# STM32H7B3ZIT6Q register map
File version: 1.0
Registers are 32-bit, access not given, reset 0x0 unless marked. A register's access mark holds for its fields unless they carry their own. Offsets are from the block's base; [hi:lo] are bit positions; {n}, {i} and the like mark numbered series; 'fields as' and 'values as' point back to an identical list.

## FMC_Bank3_R
Base 0x52004080
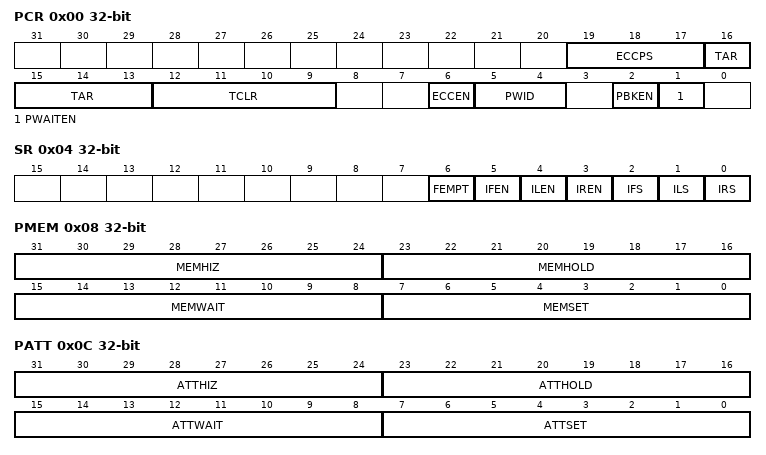
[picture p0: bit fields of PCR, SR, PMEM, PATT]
0x00 PCR
  [19:17] ECCPS, [16:13] TAR, [12:9] TCLR, [6] ECCEN, [5:4] PWID, [2] PBKEN, [1] PWAITEN
0x04 SR
  [6] FEMPT, [5] IFEN, [4] ILEN, [3] IREN, [2] IFS, [1] ILS, [0] IRS
0x08 PMEM
  [31:24] MEMHIZ, [23:16] MEMHOLD, [15:8] MEMWAIT, [7:0] MEMSET
0x0C PATT
  [31:24] ATTHIZ, [23:16] ATTHOLD, [15:8] ATTWAIT, [7:0] ATTSET
0x14 ECCR

## FMC_Bank1E_R
Base 0x52004104
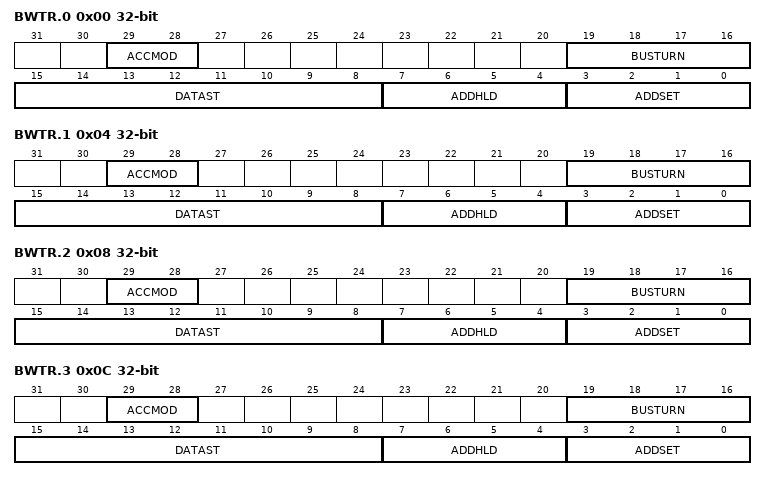
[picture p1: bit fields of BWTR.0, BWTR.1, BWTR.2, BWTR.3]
0x00 BWTR.0
  [29:28] ACCMOD, [19:16] BUSTURN, [15:8] DATAST, [7:4] ADDHLD, [3:0] ADDSET
0x04 BWTR.1
  fields as BWTR.0
0x08 BWTR.2
  fields as BWTR.0
0x0C BWTR.3
  fields as BWTR.0
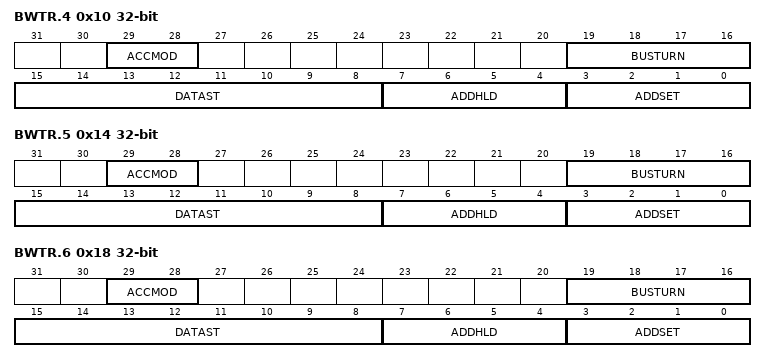
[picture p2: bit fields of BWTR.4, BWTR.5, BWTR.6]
0x10 BWTR.4
  fields as BWTR.0
0x14 BWTR.5
  fields as BWTR.0
0x18 BWTR.6
  fields as BWTR.0

## FMC_Bank5_6_R
Base 0x52004140
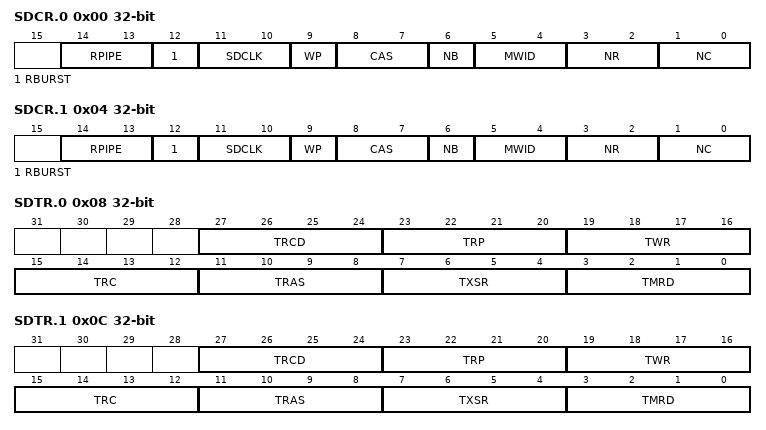
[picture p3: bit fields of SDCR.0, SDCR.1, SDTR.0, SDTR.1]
0x00 SDCR.0
  [14:13] RPIPE, [12] RBURST, [11:10] SDCLK, [9] WP, [8:7] CAS, [6] NB, [5:4] MWID, [3:2] NR, [1:0] NC
0x04 SDCR.1
  fields as SDCR.0
0x08 SDTR.0
  [27:24] TRCD, [23:20] TRP, [19:16] TWR, [15:12] TRC, [11:8] TRAS, [7:4] TXSR, [3:0] TMRD
0x0C SDTR.1
  fields as SDTR.0
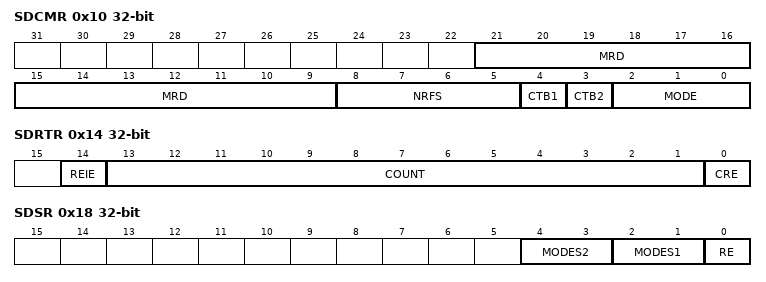
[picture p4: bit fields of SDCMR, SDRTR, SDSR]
0x10 SDCMR
  [21:9] MRD, [8:5] NRFS, [4] CTB1, [3] CTB2, [2:0] MODE
0x14 SDRTR
  [14] REIE, [13:1] COUNT, [0] CRE
0x18 SDSR
  [4:3] MODES2, [2:1] MODES1, [0] RE

## OCTOSPI1
Base 0x52005000
Same registers: OCTOSPI2 0x5200A000
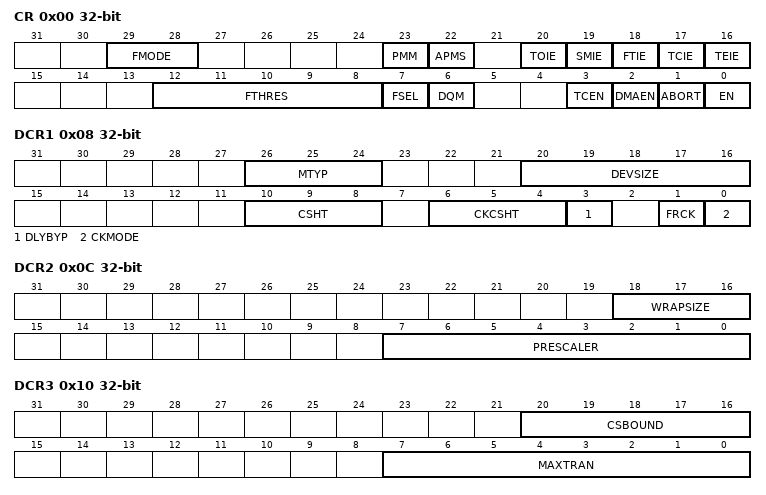
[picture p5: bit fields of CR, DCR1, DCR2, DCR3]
0x00 CR
  [29:28] FMODE, [23] PMM, [22] APMS, [20] TOIE, [19] SMIE, [18] FTIE, [17] TCIE, [16] TEIE, [12:8] FTHRES, [7] FSEL, [6] DQM, [3] TCEN, [2] DMAEN, [1] ABORT, [0] EN
0x08 DCR1
  [26:24] MTYP, [20:16] DEVSIZE, [10:8] CSHT, [6:4] CKCSHT, [3] DLYBYP, [1] FRCK, [0] CKMODE
0x0C DCR2
  [18:16] WRAPSIZE, [7:0] PRESCALER
0x10 DCR3
  [20:16] CSBOUND, [7:0] MAXTRAN
0x14 DCR4
  [31:0] REFRESH
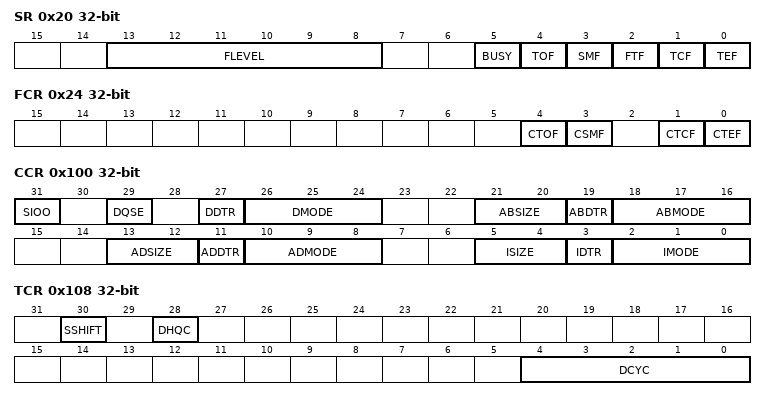
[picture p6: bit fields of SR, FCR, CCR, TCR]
0x20 SR
  [13:8] FLEVEL, [5] BUSY, [4] TOF, [3] SMF, [2] FTF, [1] TCF, [0] TEF
0x24 FCR
  [4] CTOF, [3] CSMF, [1] CTCF, [0] CTEF
0x40 DLR
  [31:0] DL
0x48 AR
  [31:0] ADDRESS
0x50 DR
  [31:0] DATA
0x80 PSMKR
  [31:0] MASK
0x88 PSMAR
  [31:0] MATCH
0x90 PIR
  [15:0] INTERVAL
0x100 CCR
  [31] SIOO, [29] DQSE, [27] DDTR, [26:24] DMODE, [21:20] ABSIZE, [19] ABDTR, [18:16] ABMODE, [13:12] ADSIZE, [11] ADDTR, [10:8] ADMODE, [5:4] ISIZE, [3] IDTR, [2:0] IMODE
0x108 TCR
  [30] SSHIFT, [28] DHQC, [4:0] DCYC
0x110 IR
  [31:0] INSTRUCTION
0x120 ABR
  [31:0] ALTERNATE
0x130 LPTR
  [15:0] TIMEOUT
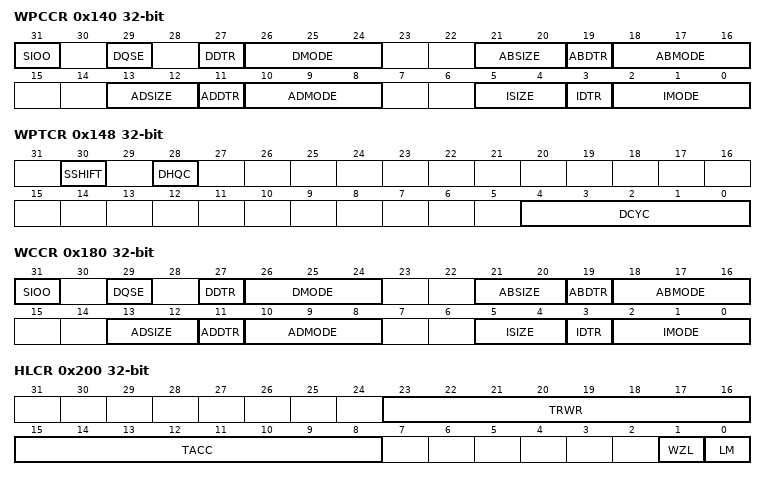
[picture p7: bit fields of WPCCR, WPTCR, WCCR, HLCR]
0x140 WPCCR
  fields as CCR
0x148 WPTCR
  [30] SSHIFT, [28] DHQC, [4:0] DCYC
0x150 WPIR
  [31:0] INSTRUCTION
0x160 WPABR
  [31:0] ALTERNATE
0x180 WCCR
  fields as CCR
0x188 WTCR
  [4:0] DCYC
0x190 WIR
  [31:0] INSTRUCTION
0x1A0 WABR
  [31:0] ALTERNATE
0x200 HLCR
  [23:16] TRWR, [15:8] TACC, [1] WZL, [0] LM
0x3EC HWCFGR
0x3F0 VER
  [7:0] VER
0x3F4 ID
0x3F8 MID

## RAMECC
Base 0x52009000
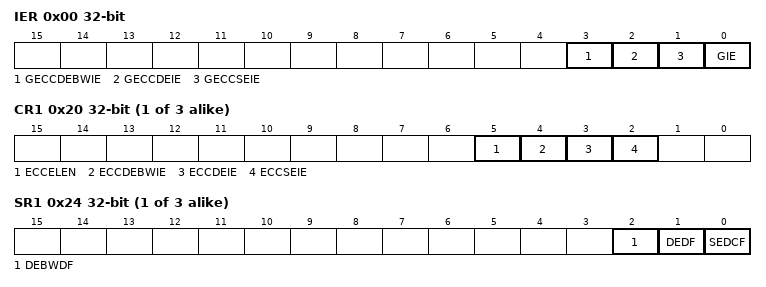
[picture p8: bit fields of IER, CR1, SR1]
0x00 IER
  [3] GECCDEBWIE, [2] GECCDEIE, [1] GECCSEIE, [0] GIE
{0x0+0x20*i} CR{i} (i=1..3)
  [5] ECCELEN, [4] ECCDEBWIE, [3] ECCDEIE, [2] ECCSEIE
{0x4+0x20*i} SR{i} (i=1..3)
  [2] DEBWDF, [1] DEDF, [0] SEDCF
{0x8+0x20*i} FAR{i} (i=1..3)
  [31:0] FDATAL
{0xC+0x20*i} FDRL{i} (i=1..3)
{0x10+0x20*i} FDRH{i} (i=1..3)
{0x14+0x20*i} FECR{i} (i=1..3)
  [31:0] FEC

## OCTOSPIM
Base 0x5200B400
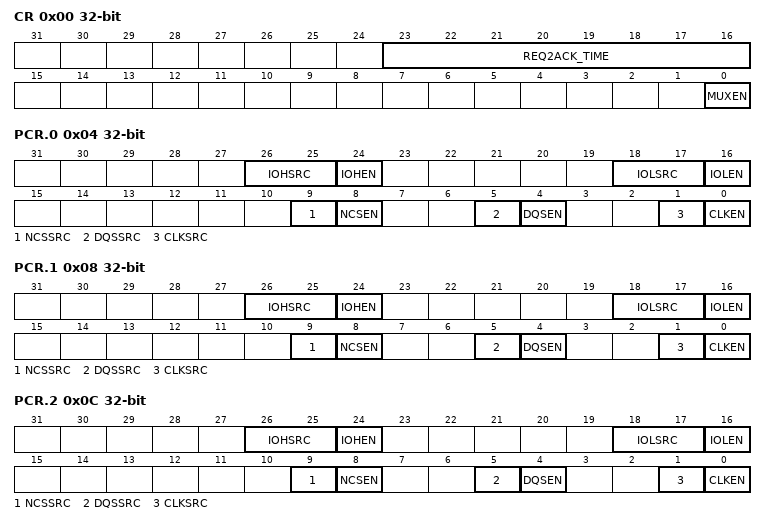
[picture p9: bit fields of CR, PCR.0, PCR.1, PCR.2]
0x00 CR
  [23:16] REQ2ACK_TIME, [0] MUXEN
0x04 PCR.0
  [26:25] IOHSRC, [24] IOHEN, [18:17] IOLSRC, [16] IOLEN, [9] NCSSRC, [8] NCSEN, [5] DQSSRC, [4] DQSEN, [1] CLKSRC, [0] CLKEN
0x08 PCR.1
  fields as PCR.0
0x0C PCR.2
  fields as PCR.0

## OTFDEC1
Base 0x5200B800
Same registers: OTFDEC2 0x5200BC00
0x00 CR
  [0] ENC
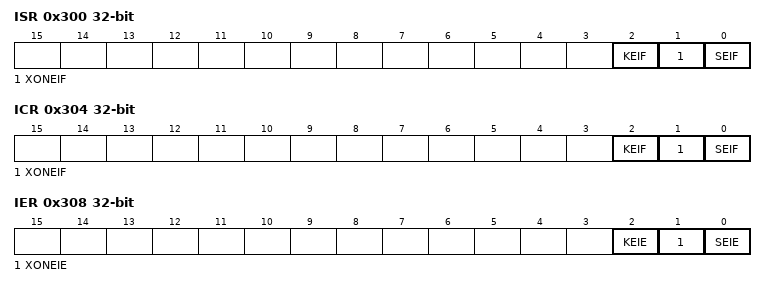
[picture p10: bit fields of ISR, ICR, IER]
0x300 ISR
  [2] KEIF, [1] XONEIF, [0] SEIF
0x304 ICR
  [2] KEIF, [1] XONEIF, [0] SEIF
0x308 IER
  [2] KEIE, [1] XONEIE, [0] SEIE
0x3EC HWCFGR2
0x3F0 HWCFGR1
0x3F4 VERR
0x3F8 IPIDR
0x3FC SIDR

## OTFDEC1_REGION1
Base 0x5200B820
Same registers: OTFDEC1_REGION2 0x5200B850, OTFDEC1_REGION3 0x5200B880, OTFDEC1_REGION4 0x5200B8B0, OTFDEC2_REGION1 0x5200BC20, OTFDEC2_REGION2 0x5200BC50, OTFDEC2_REGION3 0x5200BC80, OTFDEC2_REGION4 0x5200BCB0
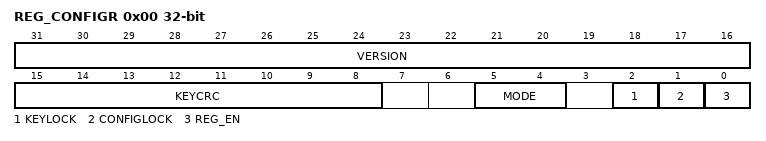
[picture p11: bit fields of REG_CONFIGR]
0x00 REG_CONFIGR
  [31:16] VERSION, [15:8] KEYCRC, [5:4] MODE, [2] KEYLOCK, [1] CONFIGLOCK, [0] REG_EN
0x04 REG_START_ADDR
0x08 REG_END_ADDR
0x0C REG_NONCER0
0x10 REG_NONCER1
{0x14+4i} REG_KEYR{i} (i=0..3)
